AUTOSAR XML (schema 4-0-3)
standard types defined: boolean, float32, float64, sint16, sint32, sint8, uint16, uint32, uint8
package /ApplDataTypes
  app type ADT_TimeCount: category=VALUE
package /HelloAutosar
  data type mapping set HA_DTM: data-type-map{application-data-type=ADT_TimeCount, implementation-data-type=IDT_TimeCount}
  composition sw component type HA_TopLevel
    component SWC1: type=SWC1
    component SWC2: type=SWC2
    connect SWC1.PPort -> SWC2.RPort
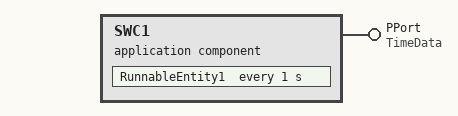
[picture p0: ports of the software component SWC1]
  application sw component type SWC1
    provide port PPort: nonqueued-sender-com-spec{data-element=time, transmission-acknowledge=timeout=0, init-value=Value:0}, provided-interface=TimeData
    behavior IB_SWC1: data-type-mapping=HA_DTM, handle-termination-and-restart=NO-SUPPORT
      timing event TimingEvent: start-on-event=RunnableEntity1, period=1
      runnable RunnableEntity1
        data-send-points:
          access VariableAccess: accessed-variable=PPort.time
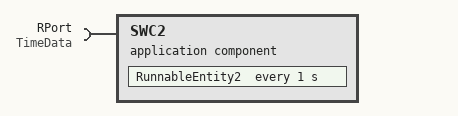
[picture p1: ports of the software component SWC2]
  application sw component type SWC2
    require port RPort: required-interface=TimeData
    behavior IB_SWC2: data-type-mapping=HA_DTM, handle-termination-and-restart=NO-SUPPORT
      timing event TimingEvent: start-on-event=RunnableEntity2, period=1
      runnable RunnableEntity2
        data-receive-point-by-arguments:
          access VariableAccess: accessed-variable=RPort.time
package /ImplDataTypes
  impl type IDT_TimeCount: category=VALUE, base-type=uint32
package /Interfaces
  sender receiver interface TimeData
    data time: type=ADT_TimeCount
package /System
  ecuc value collection EcucValueCollection: ecu-extract=SystemHA, ecuc-values=[Os, Rte, EcuC]
  system SystemHA: system-version=1.0.0
    root-software-compositions:
      root sw composition prototype RootSwCompositionPrototype: software-composition=HA_TopLevel
